AUTOSAR XML (schema 00049)
package /ISOFT/PlatformComponents/com/cg
  process design cgd_proc_design: executable=cgd
package /ISOFT/PlatformComponents/com/cg/exe
  executable cgd: category=PLATFORM_LEVEL, logging-behavior=USES-LOGGING, reporting-behavior=REPORTS-EXECUTION-STATE
    root sw component prototype root_swc: application-type=cgdemon
package /ISOFT/PlatformComponents/com/cg/swc
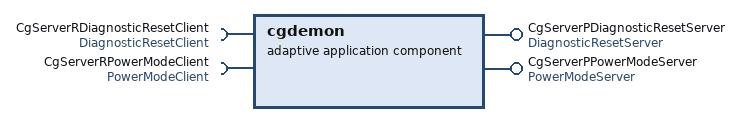
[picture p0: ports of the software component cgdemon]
  adaptive application sw component type cgdemon
    provide port CgServerPDiagnosticResetServer: provided-interface=DiagnosticResetServer
    provide port CgServerPPowerModeServer: provided-interface=PowerModeServer
    require port CgServerRDiagnosticResetClient: required-interface=DiagnosticResetClient
    require port CgServerRPowerModeClient: required-interface=PowerModeClient
